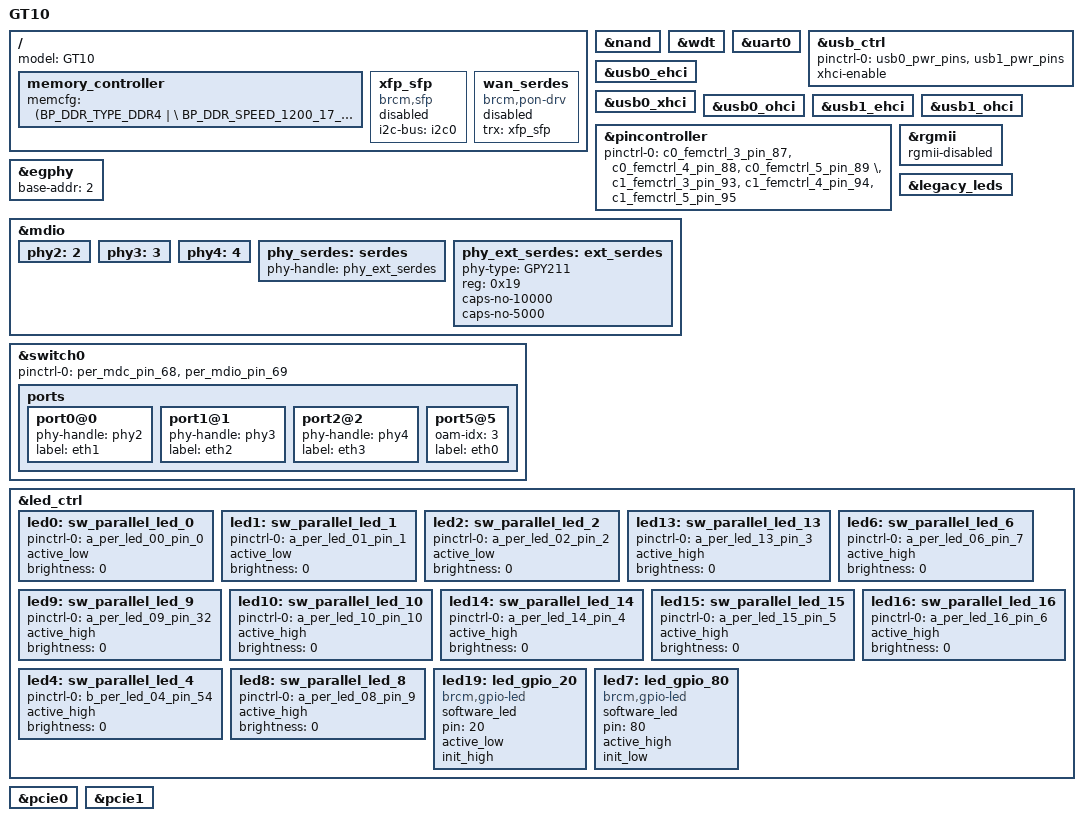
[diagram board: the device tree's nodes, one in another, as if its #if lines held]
#include "inc/6753.dtsi"

/ {
	memory_controller {
		memcfg = <(BP_DDR_TYPE_DDR4            | \
            BP_DDR_SPEED_1200_17_17_17 | \
            BP_DDR_TOTAL_SIZE_512MB   | \
            BP_DDR_DEVICE_WIDTH_16     | \
            BP_DDR_TOTAL_WIDTH_16BIT   | \
            BP_DDR_SSC_CONFIG_1)>;
	};
};

/ {
      model = "GT10";
/*
      buttons {
        compatible = "brcm,buttons";
        reset_button {
            ext_irq = <&bca_extintr 14 BCA_GPIO_ACTIVE_LOW (BCA_EXTINTR_TYPE_LOW_LEVEL | BCA_EXTINTR_TYPE_SENSE_EDGE)>;
            press {
                print = "Button Press -- Hold for 5s to do restore to default";
            };
            hold {
                rst_to_dflt = <5>;
            };
            release {
                reset = <0>;
            };
        };
        ses_button {
            ext_irq = <&bca_extintr 15 BCA_GPIO_ACTIVE_LOW (BCA_EXTINTR_TYPE_LOW_LEVEL | BCA_EXTINTR_TYPE_SENSE_EDGE)>;
            release {
                ses_short_period = <0>;
                ses_long_period = <3>;
            };
        };
    };
*/

    xfp_sfp: xfp_sfp {
        compatible = "brcm,sfp";
        i2c-bus = <&i2c0>;
        status = "disabled";
    };

    wan_serdes {
        compatible = "brcm,pon-drv";
        trx = <&xfp_sfp>;
        status = "disabled";
    };
};

&nand {
	status = "okay";
};
&wdt {
	status = "okay";
};
&uart0 {
	status = "okay";
};

&usb_ctrl {
    pinctrl-names = "default";
    pinctrl-0 = <&usb0_pwr_pins &usb1_pwr_pins>;
    xhci-enable;
    status = "okay";
};
&usb0_ehci {
    status = "okay";
};
&usb0_xhci {
    status = "okay";
};
&usb0_ohci {
    status = "okay";
};
&usb1_ehci {
    status = "okay";
};
&usb1_ohci {
    status = "okay";
};

&pincontroller {
    pinctrl-names = "default";
    pinctrl-0 = <&c0_femctrl_3_pin_87 &c0_femctrl_4_pin_88 &c0_femctrl_5_pin_89 \
                 &c1_femctrl_3_pin_93 &c1_femctrl_4_pin_94 &c1_femctrl_5_pin_95 >;
};

&rgmii {
        rgmii-disabled;
        status = "okay";
};

&egphy {
    base-addr = <2>;
};

&mdio {
    phy2:2 {
        status = "okay";
    };
    phy3:3 {
        status = "okay";
    };
    phy4:4 {
        status = "okay";
    };
    phy_serdes: serdes {
        phy-handle = <&phy_ext_serdes>;
        status = "okay";
    };
    phy_ext_serdes: ext_serdes {
        phy-type = "GPY211";
        reg = <0x19>;
        caps-no-10000;
        caps-no-5000;
        status = "okay";
    };
};

&switch0 {
    pinctrl-names = "default";
    pinctrl-0 = <&per_mdc_pin_68 &per_mdio_pin_69>;
    ports {
        port0@0 {
            phy-handle = <&phy2>;
            status = "okay";
            label = "eth1";
        };

        port1@1 {
            phy-handle = <&phy3>;
            status = "okay";
            label = "eth2";
        };

        port2@2 {
            phy-handle = <&phy4>;
            status = "okay";
            label = "eth3";
        };
        port5@5 {
            oam-idx = <3>;
            status = "okay";
            label = "eth0";
        };
    };
};

&legacy_leds {
};

&led_ctrl {
	status="okay";

	/* CLED */
	/* Main Board Indication LED Red */
	led0: sw_parallel_led_0 {
		pinctrl-0 = <&a_per_led_00_pin_0>;
		active_low;
		status="okay";
		brightness = <0>;
	};
	/* Main Board Indication LED Green */
	led1: sw_parallel_led_1 {
		pinctrl-0 = <&a_per_led_01_pin_1>;
		active_low;
		status="okay";
		brightness = <0>;
	};
	/* Main Board Indication LED Blue */
	led2: sw_parallel_led_2 {
		pinctrl-0 = <&a_per_led_02_pin_2>;
		active_low;
		status="okay";
		brightness = <0>;
	};
	/* LED Board LED Group 1 Red */
	led13: sw_parallel_led_13 {
		pinctrl-0 = <&a_per_led_13_pin_3>;
		active_high;
		status="okay";
		brightness = <0>;
	};
	/* LED Board LED Group 1 Green */
	led6: sw_parallel_led_6 {
		pinctrl-0 = <&a_per_led_06_pin_7>;
		active_high;
		status="okay";
		brightness = <0>;
	};
	/* LED Board LED Group 1 Blue */
	led9: sw_parallel_led_9 {
		pinctrl-0 = <&a_per_led_09_pin_32>;
		active_high;
		status="okay";
		brightness = <0>;
	};
	/* LED Board LED Group 2 Red */
	led10: sw_parallel_led_10 {
		pinctrl-0 = <&a_per_led_10_pin_10>;
		active_high;
		status="okay";
		brightness = <0>;
	};
	/* LED Board LED Group 2 Green */
	led14: sw_parallel_led_14 {
		pinctrl-0 = <&a_per_led_14_pin_4>;
		active_high;
		status="okay";
		brightness = <0>;
	};
	/* LED Board LED Group 2 Blue */
	led15: sw_parallel_led_15 {
		pinctrl-0 = <&a_per_led_15_pin_5>;
		active_high;
		status="okay";
		brightness = <0>;
	};
	/* LED Board LED Group 3 Red */
	led16: sw_parallel_led_16 {
		pinctrl-0 = <&a_per_led_16_pin_6>;
		active_high;
		status="okay";
		brightness = <0>;
	};
	/* LED Board LED Group 3 Green */
	led4: sw_parallel_led_4 {
		pinctrl-0 = <&b_per_led_04_pin_54>;
		active_high;
		status="okay";
		brightness = <0>;
	};
	/* LED Board LED Group 3 Blue */
	led8: sw_parallel_led_8 {
		pinctrl-0 = <&a_per_led_08_pin_9>;
		active_high;
		status="okay";
		brightness = <0>;
	};

	/* GPIO_20: POWER */
	led19:led_gpio_20 {
		compatible = "brcm,gpio-led";
		software_led;
		pin = <20>;
		active_low;
		init_high;
	};

	/* USB Power */
	led7:led_gpio_80 {
		compatible = "brcm,gpio-led";
		software_led;
		pin = <80>;
		active_high;
		init_low;
	};
};

#if defined(CONFIG_BCM_PCIE_HCD) || defined(CONFIG_BCM_PCIE_HCD_MODULE)
&pcie0 {
    status = "okay";
};
&pcie1 {
    status = "okay";
};
#endif
